# ats-intc register map
File version: 0.0
Asynchronous task scheduler and Interrupt controller description
Registers are 32-bit, read-write, reset 0x0 unless marked. A register's access mark holds for its fields unless they carry their own. Offsets are from the block's base; lines under a group give offsets from that group; [hi:lo] are bit positions; {n}, {i} and the like mark numbered series; 'fields as' and 'values as' point back to an identical list; <NAME> marks a mode.

## Memory map
0x60040000 ATS-INTC size 0x1000 — Asynchronous task scheduler and Interrupt controller description

## ATS-INTC — Asynchronous task scheduler and Interrupt controller description
Base 0x60040000
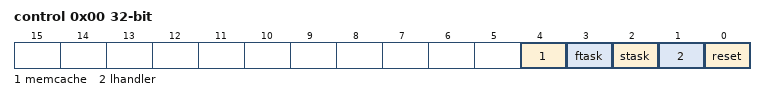
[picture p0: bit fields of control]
0x00 control — The transaction control register
  [4] memcache — When initializing, the software will alloc a memory area and set it as the Executor cache.
    0=complete; 1=start
  [3] ftask — Software fetch task flag
    0=complete; 1=start
  [2] stask — Software store task flag
    0=complete; 1=start
  [1] lhandler — Software load handler task flag
    0=complete; 1=load
  [0] reset — Software reset for reseting the executor channel
    0=complete; 1=Reset
0x04 stask_lsb — When the software store the task, it will write the register.(LSB)
0x08 stask_msb — When the software store the task, it will write the register.(MSB)
0x0C ftask_lsb — When the software fetch task, it will read from this register.(LSB)
0x10 ftask_msb — When the software fetch task, it will read from this register.(MSB)
0x14 handler_lsb — The handler task pointer lsb
0x18 handler_msb — The handler task pointer msb
0x1C irq — The irq register, when the software store handler task, it will write the relative irq.
0x20 memcache_lsb — The in-memory cache address.(LSB)
0x24 memcache_Msb — The in-memory cache address.(MSB)
0x28 priority — The task priority.
